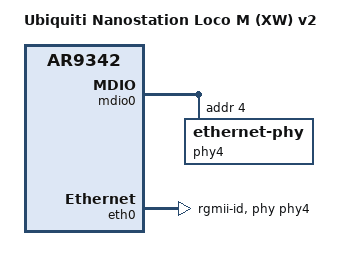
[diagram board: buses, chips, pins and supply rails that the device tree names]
// SPDX-License-Identifier: GPL-2.0-or-later OR MIT

#include "ar9342_ubnt_xw_rssileds.dtsi"

/ {
	compatible = "ubnt,nanostation-loco-m-xw-v2", "ubnt,xw", "qca,ar9342";
	model = "Ubiquiti Nanostation Loco M (XW) v2";
};

&mdio0 {
	status = "okay";

	phy4: ethernet-phy@4 {
		reg = <4>;
	};
};

&eth0 {
	status = "okay";

	/* default for ar934x, except for 1000M and 10M */
	pll-data = <0x02000000 0x00000101 0x00001313>;

	phy-mode = "rgmii-id";
	phy-handle = <&phy4>;

	gmac-config {
		device = <&gmac>;
		rxd-delay = <3>;
		rxdv-delay = <3>;
	};
};
